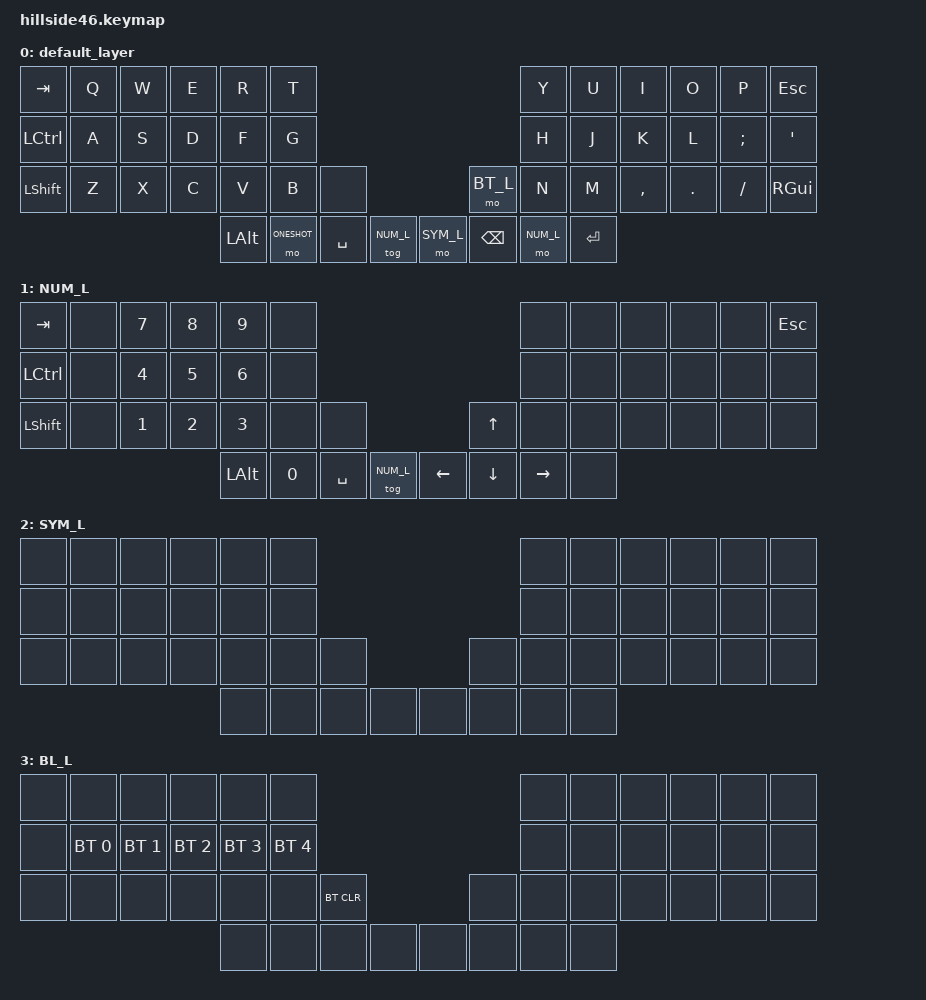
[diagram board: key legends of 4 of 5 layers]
/*
 * Copyright (c) 2021-2022 The ZMK Contributors
 *
 * SPDX-License-Identifier: MIT
 */

#include <behaviors.dtsi>
#include <dt-bindings/zmk/bt.h>
#include <dt-bindings/zmk/ext_power.h>
#include <dt-bindings/zmk/keys.h>
#include <dt-bindings/zmk/outputs.h>

#define DEFAULT_L 0
#define NUM_L 1
#define SYM_L 2
#define BT_L   3
#define ONESHOT 4


&sk {
    release-after-ms = <2000>;
};

/ {
        keymap {
                compatible = "zmk,keymap";

                default_layer {

                        bindings = <
&kp  TAB    &kp  Q        &kp  W        &kp  E        &kp  R        &kp  T                                                                 &kp  Y        &kp  U        &kp  I        &kp  O        &kp  P       &kp ESC
&kp  LCTRL   &kp  A        &kp  S        &kp  D        &kp  F        &kp  G                                                                &kp  H        &kp  J        &kp  K        &kp  L        &kp  SEMI     &kp SQT  
&kp  LSHIFT  &kp  Z        &kp  X        &kp  C        &kp  V        &kp  B        &none                                          &mo BT_L   &kp  N        &kp  M        &kp  COMMA    &kp  DOT      &kp  SLASH    &kp RGUI
                                                        &kp  LALT     &mo ONESHOT     &kp  SPACE   &tog NUM_L                  &mo SYM_L    &kp  BSPC  &mo NUM_L    &kp RET
                        >;
			
                        sensor-bindings = <&inc_dec_kp C_VOL_UP C_VOL_DN &inc_dec_kp PG_UP PG_DN>;
                };
		
		
		
               	num_layer {
		label = "NUM_L";
                        bindings = <
			
&kp  TAB       &none &kp N7 &kp N8 &kp N9 &none                                        &none &none &none &none &none &kp ESC
&kp  LCTRL    &none &kp N4 &kp N5 &kp N6 &none                                         &none &none &none &none &none &none 
&kp  LSHIFT   &none &kp N1 &kp N2 &kp N3 &none &none                                 &kp UP &none &none &none &none &none &none 
                        &kp  LALT  &kp N0 &kp SPACE &tog NUM_L              &kp LEFT &kp DOWN &kp RIGHT &none
                        
			>;
			
                        sensor-bindings = <&inc_dec_kp PG_UP PG_DN &inc_dec_kp C_VOL_UP C_VOL_DN>;
                };
		
                sym_layer {
		label = "SYM_L";
                        bindings = <
			
&none &none &none &none &none &none                                        &none &none &none &none &none &none
&none &none &none&none &none &none                                         &none &none &none &none &none &none 
&none &none &none &none &none &none &none                            &none &none &none &none &none &none &none 
                        &none &none &none &none               &none &none &none &none
                        
			>;
			
                        sensor-bindings = <&inc_dec_kp PG_UP PG_DN &inc_dec_kp C_VOL_UP C_VOL_DN>;
                };
		
                BLUETOOTH_layer {
		label = "BL_L";
                        bindings = <
			
&none 	&none	&none 	&none 	&none 	&none                                        					     &none &none &none &none &none &none
&none  	&bt  BT_SEL 0 &bt  BT_SEL 1 &bt  BT_SEL 2 &bt  BT_SEL 3 &bt  BT_SEL 4                                         &none &none &none &none &none &none 
&none 	&none 	&none 	&none 	&none 	&none  &bt BT_CLR                            				        &none &none &none &none &none &none &none 
                        &none 	&none 	&none 	&none               						  &none &none &none &none
                        
			>;
			
                        sensor-bindings = <&inc_dec_kp C_VOL_UP C_VOL_DN &inc_dec_kp PG_UP PG_DN>;
                 
		};
		
		ONESHOT_layer {
		label = "ONESHOT";
                        bindings = <
&none         &none         &none         &none         &none         &none                                                                             &none             &kp   F11          &kp   F12  &kp PRINTSCREEN   &ext_power EP_OFF  &ext_power EP_ON
&none         &sk LCTRL     &sk LGUI      &sk LALT      &sk RSHIFT     &none                                                                 &none             &none              &none            &none          &none           &bootloader
&none         &none         &none         &none         &none          &none         &none                                       &none            &none             &none              &out  OUT_USB    &out  OUT_BLE  &none           &reset
                                                         &none 	&none 	&none 	&none               						  &none &none &none &none         &trans 
                        >;
			
                        sensor-bindings = <&inc_dec_kp C_VOL_UP C_VOL_DN &inc_dec_kp PG_UP PG_DN>;
                };
        };
};
